# ENCODER0_REG_TOPAZHP_MULTICORE register map
Vendor: Texas Instruments
Peripheral module from a debugger description file (folder J7ES).
Registers are 32-bit, access per field, reset 0x0 unless marked. A register's access mark holds for its fields unless they carry their own. Offsets are as the file gives them; lines under a group give offsets from that group; [hi:lo] are bit positions; {n}, {i} and the like mark numbered series; 'fields as' and 'values as' point back to an identical list; <NAME> marks a mode.

## ENCODER0_REG_TOPAZHP_MULTICORE
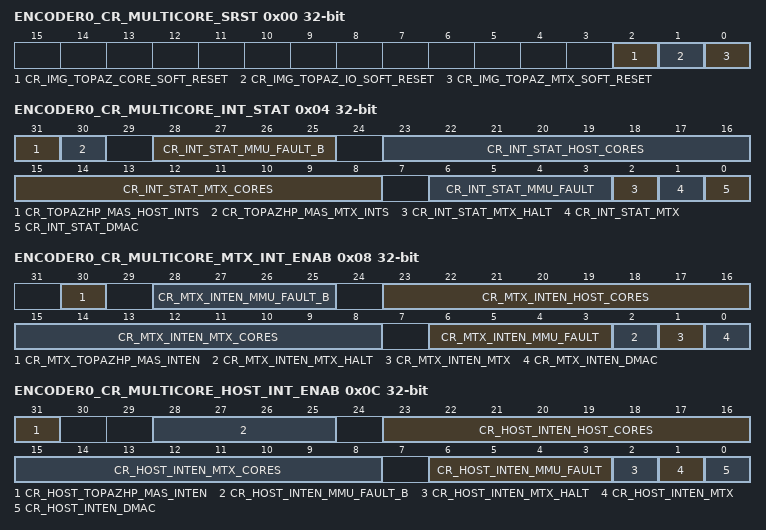
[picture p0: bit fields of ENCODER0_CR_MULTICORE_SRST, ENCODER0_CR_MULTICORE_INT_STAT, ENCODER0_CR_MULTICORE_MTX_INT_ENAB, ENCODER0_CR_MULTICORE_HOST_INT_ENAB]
0x00 ENCODER0_CR_MULTICORE_SRST — It is important that the correct procedure is used when the host software-resets the MTX and the topazHP cores using the MULTICORE_SRST register. This procedure ensures that MTX is inactive before the surrounding logic is reset. Failing to do this may result in the system bus locking up if MTX is active whilst the software reset is used. Disable MTX by writing zero to the MTX_ENABLE register. Software reset MTX only by writing 0x1 then 0x0 to the MULTICORE_SRST register. Software reset MTX, cores, and IO by writing 0x7 then 0x0 to the MULTICORE_SRST register.
  [2] CR_IMG_TOPAZ_CORE_SOFT_RESET rw — Core software reset:
  [1] CR_IMG_TOPAZ_IO_SOFT_RESET rw — IO Software reset:
  [0] CR_IMG_TOPAZ_MTX_SOFT_RESET rw — MTX Software reset:
0x04 ENCODER0_CR_MULTICORE_INT_STAT
  [31] CR_TOPAZHP_MAS_HOST_INTS rw — Status of TopazHP interrupt due to Host enable register
  [30] CR_TOPAZHP_MAS_MTX_INTS rw — Status of TopazHP interrupt due to MTX enable register
  [28:25] CR_INT_STAT_MMU_FAULT_B rw — 4 bit indicating a page fault [Pulse generated at event, held by edge detection logic].
  [23:16] CR_INT_STAT_HOST_CORES rw — Indicates which instances of TopazHP core are currently issuing an IRQ due to the Host enable register.
  [15:8] CR_INT_STAT_MTX_CORES rw — Indicates which instances of TopazHP core are currently issuing an IRQ due to the MTX enable register.
  [6:3] CR_INT_STAT_MMU_FAULT rw — 4 bit indicating a page fault [Pulse generated at event, held by edge detection logic].
  [2] CR_INT_STAT_MTX_HALT rw — MTX_HALT interrupt status
  [1] CR_INT_STAT_MTX rw — MTX interrupt status
  [0] CR_INT_STAT_DMAC rw
0x08 ENCODER0_CR_MULTICORE_MTX_INT_ENAB — Two interrupt signals are generated by the core. The same interrupt sources are used, but different interrupt masks can be applied. This is mainly intended so that one interrupt is used by MTX, and the other interrupt is used by the Host.
  [30] CR_MTX_TOPAZHP_MAS_INTEN rw — Master interrupt enable
  [28:25] CR_MTX_INTEN_MMU_FAULT_B rw — 0 : Disables MMU_FAULT interrupts
  [23:16] CR_MTX_INTEN_HOST_CORES rw — Indicates which instances of TopazHP core CORE_HOST_IRQ are currently enabled as interrupt source.
  [15:8] CR_MTX_INTEN_MTX_CORES rw — Indicates which instances of TopazHP core CORE_MTX_IRQ are currently enabled as interrupt source.
  [6:3] CR_MTX_INTEN_MMU_FAULT rw — 0 : Disables MMU_FAULT interrupts
  [2] CR_MTX_INTEN_MTX_HALT rw
  [1] CR_MTX_INTEN_MTX rw
  [0] CR_MTX_INTEN_DMAC rw
0x0C ENCODER0_CR_MULTICORE_HOST_INT_ENAB
  [31] CR_HOST_TOPAZHP_MAS_INTEN rw — Master interrupt enable
  [28:25] CR_HOST_INTEN_MMU_FAULT_B rw — 0 : Disables MMU_FAULT interrupts
  [23:16] CR_HOST_INTEN_HOST_CORES rw — Indicates which instances of TopazHP core CORE_HOST_IRQ are currently enabled as interrupt source.
  [15:8] CR_HOST_INTEN_MTX_CORES rw — Indicates which instances of TopazHP core CORE_MTX_IRQ are currently enabled as interrupt source.
  [6:3] CR_HOST_INTEN_MMU_FAULT rw — 0 : Disables MMU_FAULT interrupts
  [2] CR_HOST_INTEN_MTX_HALT rw
  [1] CR_HOST_INTEN_MTX rw — 0 : Disables MTX interrupts
  [0] CR_HOST_INTEN_DMAC rw
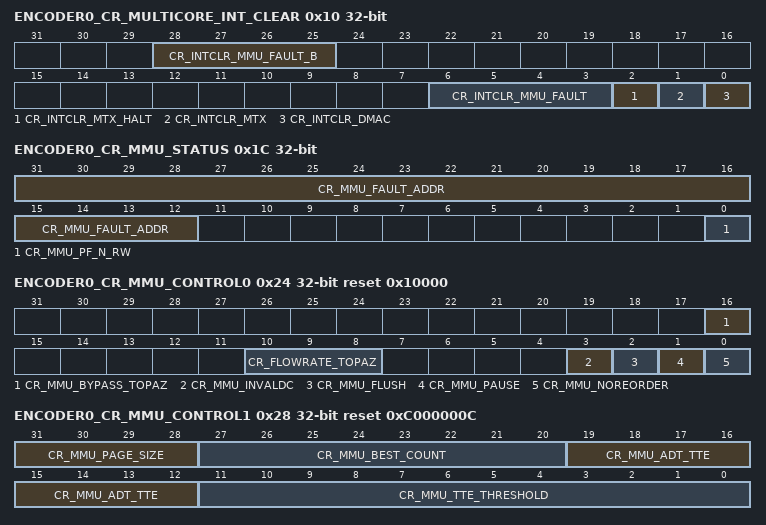
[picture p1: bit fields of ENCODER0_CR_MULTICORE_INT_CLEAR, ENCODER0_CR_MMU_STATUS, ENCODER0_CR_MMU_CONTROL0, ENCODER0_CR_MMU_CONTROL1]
0x10 ENCODER0_CR_MULTICORE_INT_CLEAR — The value read from the MULTICORE_INT_STAT interrupt status register is based on 'input source' ORed with 'rising edge detection' logic. Either the rising edge of a level based interrupt or the rising edge of a pulse inperrupt will be latched by the rising edge detection circuit. Writing '1' to this register clears the relevant 'edge detection' bit in the interrupt status register when the respective bit of write data bit is set. If the edge detect bit is 0, write has no affect. In the case of level based sources, the value read from the interrupt status register will remain high until the source generating the level is cleared. Edge detection logic is not applied to the interrupts generated by each core, because similar status clearing registers exist for each individial source in each core.
  [28:25] CR_INTCLR_MMU_FAULT_B rw — 1 : Clear MMU fault interrupt [clears fault caused by either TopazHP cores or by the DMAC]
  [6:3] CR_INTCLR_MMU_FAULT rw — 1 : Clear MMU fault interrupt [clears fault caused by either TopazHP cores or by the DMAC]
  [2] CR_INTCLR_MTX_HALT rw
  [1] CR_INTCLR_MTX rw
  [0] CR_INTCLR_DMAC rw
0x14 ENCODER0_CR_MULTICORE_MAN_CLK_GATE
  [1] CR_TOPAZ_MTX_MAN_CLK_GATE rw — MTX manual clock gate:
0x18 ENCODER0_CR_TOPAZ_MTX_C_RATIO — Reserved for internal use
  [1:0] CR_MTX_C_RATIO rw — sys_clk : mtx_clk clock ratio
0x1C ENCODER0_CR_MMU_STATUS ro
  [31:12] CR_MMU_FAULT_ADDR — Page-aligned address causing page fault
  [0] CR_MMU_PF_N_RW — Indicates whether the current fault is a page or R/W protection fault
0x20 ENCODER0_CR_MMU_MEM_REQ ro
  [7:0] CR_MEM_REQ_STAT_READS — This is the number of outstanding read requests.
0x24 ENCODER0_CR_MMU_CONTROL0 reset 0x10000
  [16] CR_MMU_BYPASS_TOPAZ rw — Setting this bit to a '1' bypasses the MMU for the TopazHP cores and the DMAC
  [10:8] CR_FLOWRATE_TOPAZ rw — Flowrate control for TopazHP cores
  [3] CR_MMU_INVALDC rw — Writing '1' causes flushing of directory cache [and all other caches and tlbs] [The flush is triggered by the act of writing '1' to this bit, but the flush will complete and MMU will continue to function if the bit is left high.
  [2] CR_MMU_FLUSH rw — Writing '1' causes flushing of address translation cache and all tlbs [The MMU will remain in Flush state until the bit is cleared by writing '0'.
  [1] CR_MMU_PAUSE rw — Writing '1' causes MMU operation to pause [The MMU will remain paused until the bit is cleared by writing '0']
  [0] CR_MMU_NOREORDER rw — Writing '1' disables transaction re-ordering by signalling to the external SoC infrastructure to closely order the requests [debug only]
0x28 ENCODER0_CR_MMU_CONTROL1 rw reset 0xC000000C
  [31:28] CR_MMU_PAGE_SIZE — Page size control for memory arbiter - the value corresponds to the lsb position of the page size
  [27:20] CR_MMU_BEST_COUNT — Best count for memory arbiter
  [19:12] CR_MMU_ADT_TTE — TTE value for ADT
  [11:0] CR_MMU_TTE_THRESHOLD — TTE threshold for memory arbiter
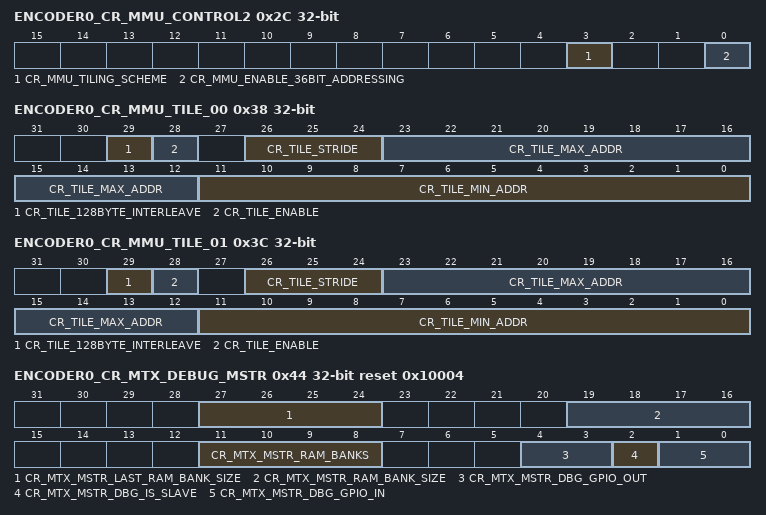
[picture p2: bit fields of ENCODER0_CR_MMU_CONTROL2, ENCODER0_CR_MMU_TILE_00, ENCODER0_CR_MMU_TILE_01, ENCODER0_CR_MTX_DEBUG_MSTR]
0x2C ENCODER0_CR_MMU_CONTROL2
  [3] CR_MMU_TILING_SCHEME rw — This bit controls the tiling scheme described in MMU Address Translation section.
  [0] CR_MMU_ENABLE_36BIT_ADDRESSING rw — Setting this bit to a value of 1 enables the extended MMU addressing [i.e.
0x30 ENCODER0_CR_MMU_DIR_LIST_BASE_00
  [31:4] CR_MMU_DIR_LIST_BASE_ADDR rw — Base address in physical memory for MMU Directory 1 Entries.
0x38 ENCODER0_CR_MMU_TILE_00
  [29] CR_TILE_128BYTE_INTERLEAVE rw — If DDR is arranged so that 128 bytes go to one bank, and the next 128 bytes go to a different bank row accesses into a tile could be more efficient if they swap order every 128 bytes
  [28] CR_TILE_ENABLE rw — 0 : Memory Tiling Disabled
  [26:24] CR_TILE_STRIDE rw — Defines the X Tile Stride for the memory address range
  [23:12] CR_TILE_MAX_ADDR rw — Defines the address for tiling range, in trems of the address MSB's i.e.
  [11:0] CR_TILE_MIN_ADDR rw — Defines the minimum address for range tiling range, in terms of the address MSB's i.e.
0x3C ENCODER0_CR_MMU_TILE_01
  fields as ENCODER0_CR_MMU_TILE_00
0x44 ENCODER0_CR_MTX_DEBUG_MSTR reset 0x10004
  [27:24] CR_MTX_MSTR_LAST_RAM_BANK_SIZE rw — Defines size of last RAM bank, where size is 2^[MTX_LAST_RAM_BANK_SIZE+2] bytes
  [19:16] CR_MTX_MSTR_RAM_BANK_SIZE rw — Defines size of all but last bank, where size is 2^[MTX_RAM_BANK_SIZE+2] bytes
  [11:8] CR_MTX_MSTR_RAM_BANKS rw — Number of MTX RAM banks
  [4:3] CR_MTX_MSTR_DBG_GPIO_OUT rw — Data provided by dbg_gpio_out by MTX.
  [2] CR_MTX_MSTR_DBG_IS_SLAVE rw — Determines whether the jtag port of MTX is to be master or slave
  [1:0] CR_MTX_MSTR_DBG_GPIO_IN rw — Data for dbg_gpio_in for MTX
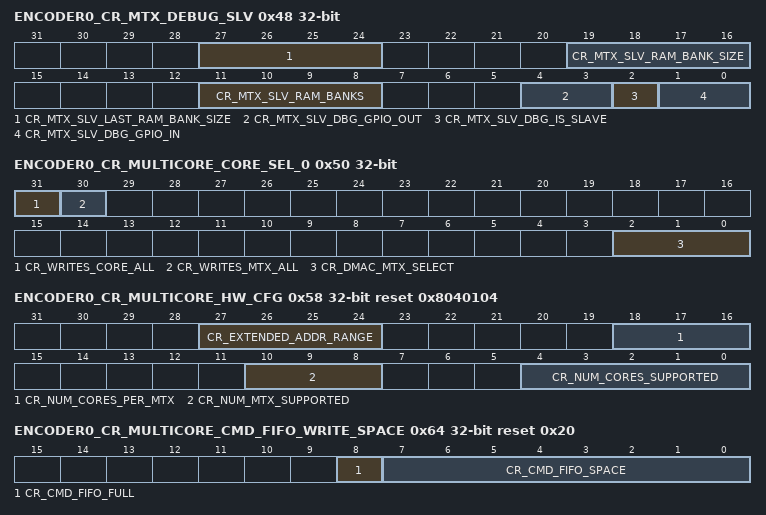
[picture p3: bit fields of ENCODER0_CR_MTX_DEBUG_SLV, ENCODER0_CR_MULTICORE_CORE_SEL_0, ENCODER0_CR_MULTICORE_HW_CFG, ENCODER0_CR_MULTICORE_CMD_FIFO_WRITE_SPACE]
0x48 ENCODER0_CR_MTX_DEBUG_SLV
  [27:24] CR_MTX_SLV_LAST_RAM_BANK_SIZE rw — Defines size of last RAM bank, where size is 2^[MTX_LAST_RAM_BANK_SIZE+2] bytes
  [19:16] CR_MTX_SLV_RAM_BANK_SIZE rw — Defines size of all but last bank, where size is 2^[MTX_RAM_BANK_SIZE+2] bytes
  [11:8] CR_MTX_SLV_RAM_BANKS rw — Number of MTX RAM banks
  [4:3] CR_MTX_SLV_DBG_GPIO_OUT rw — Data provided by dbg_gpio_out by MTX.
  [2] CR_MTX_SLV_DBG_IS_SLAVE rw — Determines whether the jtag port of MTX is to be master or slave
  [1:0] CR_MTX_SLV_DBG_GPIO_IN rw — Data for dbg_gpio_in for MTX
0x50 ENCODER0_CR_MULTICORE_CORE_SEL_0
  [31] CR_WRITES_CORE_ALL rw — 0 : Write accesses will be sent to one instance of TopazHP core depending on the address
  [30] CR_WRITES_MTX_ALL rw — 0 : Write accesses will be sent to one MTX depending on the address
  [2:0] CR_DMAC_MTX_SELECT rw — The topaz_core number to which a DMA transfer is targeted.
0x54 ENCODER0_CR_MULTICORE_CORE_SEL_1
  [4:0] CR_RTM_PORT_CORE_SELECT rw — The number of the instance of TopazHP core to which the external RTM ports will be connected
0x58 ENCODER0_CR_MULTICORE_HW_CFG ro reset 0x8040104
  [27:24] CR_EXTENDED_ADDR_RANGE — The number of physical address bits - 32, where a value of 0 indicates
  [18:16] CR_NUM_CORES_PER_MTX — The number of TopazHP cores that are controlled by each MTX
  [10:8] CR_NUM_MTX_SUPPORTED — The number of instances of MTX that are present
  [4:0] CR_NUM_CORES_SUPPORTED — The number of instances of TopazHP core that are present
0x60 ENCODER0_CR_MULTICORE_CMD_FIFO_WRITE rw
  [31:0] CR_CMD_FIFO_WDATA — Data written to this register is stored into the command FIFO.
0x64 ENCODER0_CR_MULTICORE_CMD_FIFO_WRITE_SPACE ro reset 0x20
  [8] CR_CMD_FIFO_FULL — 0 : The command FIFO has space in it for at least 1 word
  [7:0] CR_CMD_FIFO_SPACE — The number of words of space available in the command FIFO.
0x70 ENCODER0_CR_TOPAZ_CMD_FIFO_READ rw
  [31:0] CR_CMD_FIFO_RDATA — Data from the command FIFO can be read by reading this register.
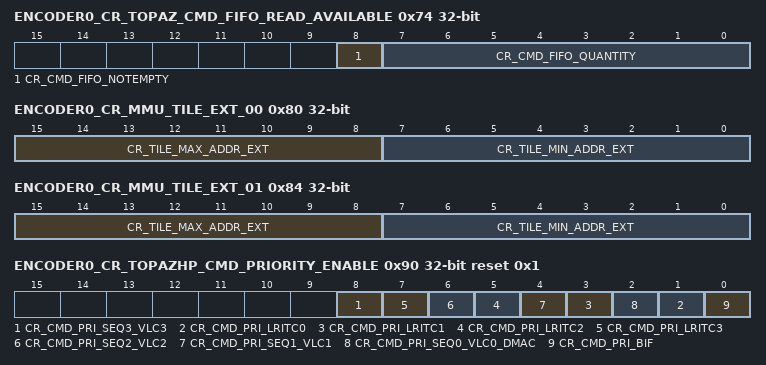
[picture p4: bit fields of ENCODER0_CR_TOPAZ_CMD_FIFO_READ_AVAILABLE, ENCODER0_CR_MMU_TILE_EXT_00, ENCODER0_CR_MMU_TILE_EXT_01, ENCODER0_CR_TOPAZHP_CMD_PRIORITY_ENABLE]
0x74 ENCODER0_CR_TOPAZ_CMD_FIFO_READ_AVAILABLE ro
  [8] CR_CMD_FIFO_NOTEMPTY — 0 : The command FIFO is empty.
  [7:0] CR_CMD_FIFO_QUANTITY — The number of words of data that are available to be read from the command FIFO
0x78 ENCODER0_CR_TOPAZ_CMD_FIFO_FLUSH
  [0] CR_CMD_FIFO_FLUSH rw — The action of writing 1 to this register causes all the data currently in the command FIFO to be discarded.
0x80 ENCODER0_CR_MMU_TILE_EXT_00
  [15:8] CR_TILE_MAX_ADDR_EXT rw — Defines the extended part of max address for tiling range, in terms of the address LSB's i.e.
  [7:0] CR_TILE_MIN_ADDR_EXT rw — Defines the extended part of min address for tiling range, in terms of the address LSB's i.e.
0x84 ENCODER0_CR_MMU_TILE_EXT_01
  fields as ENCODER0_CR_MMU_TILE_EXT_00
0x90 ENCODER0_CR_TOPAZHP_CMD_PRIORITY_ENABLE reset 0x1 — This register enables the mem_cmd_priority output for each TopazHP BIF requestor individually. The mem_cmd_priority output is set per memory transaction to indicate to the bus fabric that the transaction is more critical to performance than other requests. Each requestor may have the priority enabled independently. The BIF defaults to high priority on reset for MMU page tables. Note that high priority transactions (as enabled by this register) will not be stalled when the mem_limited_throughput input is set. Transactions issued by the BIF for MMU page table fetches will never be stalled regardless of whether the CMD_PRI_BIF register bit is set.
  [8] CR_CMD_PRI_SEQ3_VLC3 rw — The mem_cmd_priority output may be set for SEQ3 / VLC3 memory transactions when enabled.
  [2n+1] CR_CMD_PRI_LRITC{n} rw (n=0..3) — The mem_cmd_priority output may be set for LRITC{n} memory transactions when enabled.
  [6] CR_CMD_PRI_SEQ2_VLC2 rw — The mem_cmd_priority output may be set for SEQ2 / VLC2 memory transactions when enabled.
  [4] CR_CMD_PRI_SEQ1_VLC1 rw — The mem_cmd_priority output may be set for SEQ1 / VLC1 memory transactions when enabled.
  [2] CR_CMD_PRI_SEQ0_VLC0_DMAC rw — The mem_cmd_priority output may be set for SEQ0 / VLC0 / DMAC memory transactions when enabled.
  [0] CR_CMD_PRI_BIF rw — The mem_cmd_priority output may be set for BIF [MMU] memory transactions when enabled.
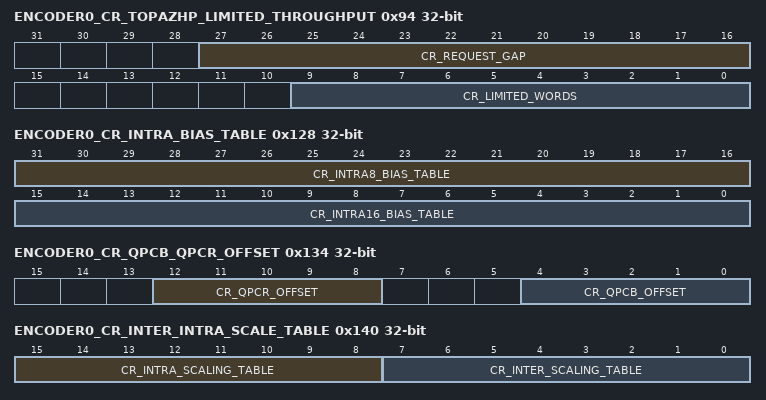
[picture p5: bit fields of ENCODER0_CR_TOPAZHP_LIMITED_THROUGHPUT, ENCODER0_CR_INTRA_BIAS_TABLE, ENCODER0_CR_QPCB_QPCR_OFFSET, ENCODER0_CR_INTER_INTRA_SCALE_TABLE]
0x94 ENCODER0_CR_TOPAZHP_LIMITED_THROUGHPUT — This register controls the memory bus stalling behaviour which occurs when the mem_limited_thrughput input is set. The mem_limited_throughput input is set by the bus fabric to indicate to TopazHP that the bus infrastructure is becoming saturated and that higher priority requests should not be blocked by lower priority requests. When the mem_limited_throughput input is set, no additional normal priority requests (with the exception of BIF (MMU) requests) are made for the duration of the request gap (counting the REQUEST_GAP number of clock cycles). Once the request gap is complete, the number of words of normal priority requests is counted up to the limited number of words (LIMITED_WORDS). Any burst transactions in progress are allowed to complete before stalling of normal priority requests recommences for the duration of the request gap. When the mem_limited_throughput input is cleared the counters are disabled (set to zero) and all requests proceed without limit. High priority requests (as defined by the CMD_PRIORITY_ENABLE register) are not stalled and pass unheeded. Requests issued by the BIF for MMU page table fetches always pass unheeded regardless of the value in the CMD_PRIORITY_ENABLE register. When either REQUEST_GAP or LIMITED_WORDS is set to zero the counters are disabled (set to zero) and all memory requests pass unheeded.
  [27:16] CR_REQUEST_GAP rw — Number of clock cycles in the range {0,4095} for which normal priority memory requests are stalled when the mem_limited_throughput input is set.
  [9:0] CR_LIMITED_WORDS rw — Number of normal priority words in the range {0,1023} that can be issued by all requestors combined before applying a request gap when the mem_limited_throughput input is set.
{0xFC+4i} ENCODER0_CR_FIRMWARE_REG_{i} rw (i=1..3)
  [31:0] CR_FIRMWARE_REG_{i} — General purpose register for software use
0x110 ENCODER0_CR_CYCLE_COUNTER rw — This counter can be used to keep track of the rate at which the core is encoding macroblocks. To measure frame rate, clear at the start of a frame and read back the value at the end of the frame.
  [31:0] CR_CYCLE_COUNTER — 32-bit cycle counter, when enabled increments by 1 each clock cycle.
0x114 ENCODER0_CR_CYCLE_COUNTER_CTRL
  [0] CR_CYCLE_COUNTER_ENABLE rw
0x118 ENCODER0_CR_MULTICORE_IDLE_PWR_MAN
  [0] CR_TOPAZ_IDLE_DISABLE rw — This field can be used to disable the topaz_idle power management output.
0x124 ENCODER0_CR_DIRECT_BIAS_TABLE — The input to the Direct_Bias shift register based table. Direct_Bias is used to bias selection towards selecting Direct mode output, which is Skip MV(P slice)/Direct mode(Bslice).
  [14:0] CR_DIRECT_BIAS_TABLE rw — Link to the Direct bias table, which is shift register based [52 entries]
0x128 ENCODER0_CR_INTRA_BIAS_TABLE rw
  [31:16] CR_INTRA8_BIAS_TABLE — Firmware stores the signed INTRA_8x8_BIAS table entries here in decrementing order [27 entries]
  [15:0] CR_INTRA16_BIAS_TABLE — Firmware stores the signed INTRA_16x16_BIAS table entries here in decrementing order [27 entries]
0x12C ENCODER0_CR_INTER_BIAS_TABLE — Firmware store the SPE_INTER_BIAS table entries here one by one in decrementing order.
  [15:0] CR_INTER_BIAS_TABLE rw — Firmware store the signed INTER_BIAS table entries here in decrementing order [27 entries]
0x130 ENCODER0_CR_INTRA_SCALE_TABLE
  [2:0] CR_INTRA8_SCALE_TABLE rw — Firmware stores the signed INTRA_8x8_SCALE table entries here in decrementing order [27 entries]
0x134 ENCODER0_CR_QPCB_QPCR_OFFSET
  [12:8] CR_QPCR_OFFSET rw — Signed offset added to QPy [and then clipped to range 0 to 51] which is used to look-up QPCr from the QPC lookup table.
  [4:0] CR_QPCB_OFFSET rw — Signed offset added to QPy [and then clipped to range 0 to 51] which is used to look-up QPCb from the QPC lookup table.
0x140 ENCODER0_CR_INTER_INTRA_SCALE_TABLE
  [15:8] CR_INTRA_SCALING_TABLE rw — Firmware stores the INTRA_SCALING table here in decrementing order [8 entries]
  [7:0] CR_INTER_SCALING_TABLE rw — Firmware stores the INTER_SCALING table here in decrementing order [8 entries]
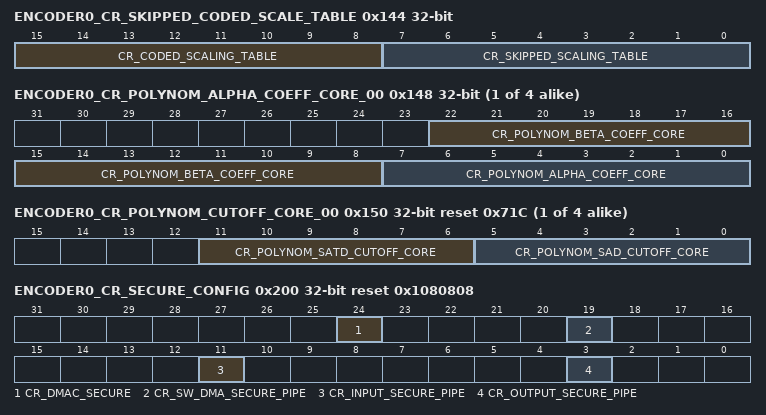
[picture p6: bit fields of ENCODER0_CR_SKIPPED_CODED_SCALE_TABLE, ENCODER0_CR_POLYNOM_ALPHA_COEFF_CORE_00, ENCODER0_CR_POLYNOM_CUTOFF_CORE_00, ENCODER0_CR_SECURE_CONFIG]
0x144 ENCODER0_CR_SKIPPED_CODED_SCALE_TABLE
  [15:8] CR_CODED_SCALING_TABLE rw — Firmware stores the CODED_SCALING table here in decrementing order [8 entries]
  [7:0] CR_SKIPPED_SCALING_TABLE rw — Firmware stores the SKIPPED_SCALING table here in decrementing order [8 entries]
{0x148+0xC*i} ENCODER0_CR_POLYNOM_ALPHA_COEFF_CORE_{i:02} (i=0..3) — alpha and betta coeffs for lambda table polynomial
  [22:8] CR_POLYNOM_BETA_COEFF_CORE rw — beta coeff for the lambda polynomial [x term], shift register, shift in the following order.
  [7:0] CR_POLYNOM_ALPHA_COEFF_CORE rw — alpha coeff for the lambda polynomial [x squared term], shift register, shift in the following order.
{0x14C+0xC*i} ENCODER0_CR_POLYNOM_GAMMA_COEFF_CORE_{i:02} (i=0..3)
  [17:0] CR_POLYNOM_GAMMA_COEFF_CORE rw — Gamma coeff for the lambda polynomial [constant term], shift register, shift in the following order
{0x150+0xC*i} ENCODER0_CR_POLYNOM_CUTOFF_CORE_{i:02} reset 0x71C (i=0..3)
  [11:6] CR_POLYNOM_SATD_CUTOFF_CORE rw — Cutoff for the change between the lower and higher qp set of coeffs for the polynomial, greater or equal to this value of qp the polynomial uses the second set of coeffs.
  [5:0] CR_POLYNOM_SAD_CUTOFF_CORE rw — Cutoff for the change between the lower and higher qp set of coeffs for the polynomial, greater or equal to this value of qp the polynomial uses the second set of coeffs.
0x200 ENCODER0_CR_SECURE_CONFIG reset 0x1080808 — This register controls the 'secure' status of AXI memory bus transactions issued by the encoder. On devices that are configured to use the IMGBus2 memory bus interface this register should not be used.
  [24] CR_DMAC_SECURE rw — 0: Memory bus transactions issued by the DMAC are marked as 'non-secure'
  [19] CR_SW_DMA_SECURE_PIPE rw — 0: Memory bus transactions issued by the S/W DMA are marked as 'non-secure'
  [11] CR_INPUT_SECURE_PIPE rw — 0: Memory bus transactions issued by the encoder for reading in current pixel data are marked as 'non-secure'
  [3] CR_OUTPUT_SECURE_PIPE rw — 0: Memory bus transactions issued by the encoder for the following data categories are marked as 'non-secure'
{0x2F0+4i} ENCODER0_CR_FIRMWARE_REG_{i} rw (i=4..7)
  fields as ENCODER0_CR_FIRMWARE_REG_1
0x3B0 ENCODER0_CR_MULTICORE_RSVD0
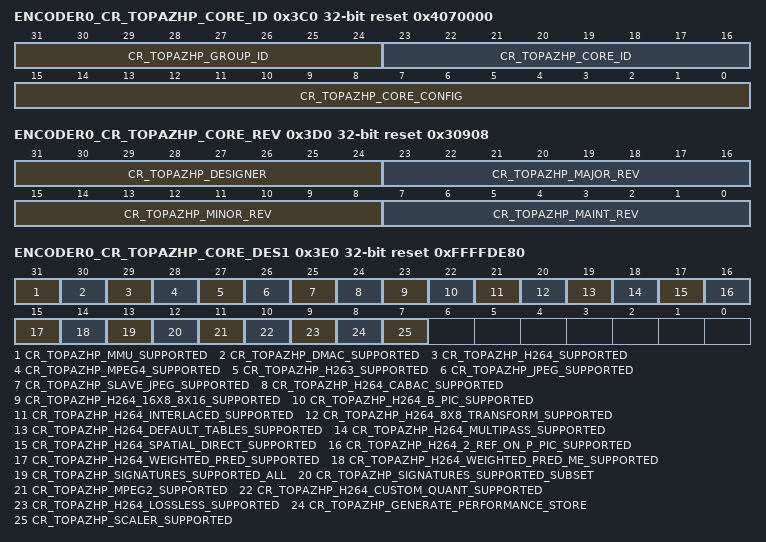
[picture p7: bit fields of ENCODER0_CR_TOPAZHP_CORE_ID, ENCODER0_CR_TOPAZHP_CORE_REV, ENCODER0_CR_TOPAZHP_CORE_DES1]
0x3C0 ENCODER0_CR_TOPAZHP_CORE_ID ro reset 0x4070000
  [31:24] CR_TOPAZHP_GROUP_ID — This identifies the as part of an IMG IP family group.
  [23:16] CR_TOPAZHP_CORE_ID — This identifies the member of the Ip group
  [15:0] CR_TOPAZHP_CORE_CONFIG — IMG Core Configuration.
0x3D0 ENCODER0_CR_TOPAZHP_CORE_REV ro reset 0x30908
  [31:24] CR_TOPAZHP_DESIGNER — Designer Code
  [23:16] CR_TOPAZHP_MAJOR_REV — IMG Family Major Revision
  [15:8] CR_TOPAZHP_MINOR_REV — IMG Core Minor Revision
  [7:0] CR_TOPAZHP_MAINT_REV — IMG Maintenance Revision
0x3E0 ENCODER0_CR_TOPAZHP_CORE_DES1 ro reset 0xFFFFDE80 — This register contains fields indicating which settings were enabled in the custom pack for this instance of the core.
  [31] CR_TOPAZHP_MMU_SUPPORTED — When set, this indicates that MMU support is enabled in this module.
  [30] CR_TOPAZHP_DMAC_SUPPORTED — When set, this indicates that DMAC support is enabled in this module.
  [29] CR_TOPAZHP_H264_SUPPORTED — When set, this indicates that H264 support is enabled in this module.
  [28] CR_TOPAZHP_MPEG4_SUPPORTED — When set, this indicates that MPEG4 support is enabled in this module.
  [27] CR_TOPAZHP_H263_SUPPORTED — When set, this indicates that H.236 support is enabled in this module.
  [26] CR_TOPAZHP_JPEG_SUPPORTED — When set, this indicates that JPEG support is enabled on pipe 0 in this module.
  [25] CR_TOPAZHP_SLAVE_JPEG_SUPPORTED — When set, this indicates that JPEG support is enabled on other pipes in this module.
  [24] CR_TOPAZHP_H264_CABAC_SUPPORTED — When set, this indicates that CABAC support is enabled in this module.
  [23] CR_TOPAZHP_H264_16X8_8X16_SUPPORTED — When set, this indicates that 16x8 and 8x16 macroblock partition support is enabled in this module.
  [22] CR_TOPAZHP_H264_B_PIC_SUPPORTED — When set, this indicates that B picture support is enabled in this module.
  [21] CR_TOPAZHP_H264_INTERLACED_SUPPORTED — When set, this indicates that H264 interlace support is enabled in this module.
  [20] CR_TOPAZHP_H264_8X8_TRANSFORM_SUPPORTED — When set, this indicates that H264 8x8 transform is enabled in this module.
  [19] CR_TOPAZHP_H264_DEFAULT_TABLES_SUPPORTED — When set, this indicates that H264 default scaling list quantisation support is enabled in this module.
  [18] CR_TOPAZHP_H264_MULTIPASS_SUPPORTED — When set, this indicates that multipass support is enabled in this module.
  [17] CR_TOPAZHP_H264_SPATIAL_DIRECT_SUPPORTED — When set, this indicates that spatial direct mode support is enabled in this module.
  [16] CR_TOPAZHP_H264_2_REF_ON_P_PIC_SUPPORTED — When set, this indicates that the use of 2 reference pictures on a P picture is enabled in this module.
  [15] CR_TOPAZHP_H264_WEIGHTED_PRED_SUPPORTED — When set, this indicates that weighted prediction support is enabled in this module.
  [14] CR_TOPAZHP_H264_WEIGHTED_PRED_ME_SUPPORTED — When set, this indicates that weighted prediction support [for motion estimation] is enabled in this module.
  [13] CR_TOPAZHP_SIGNATURES_SUPPORTED_ALL — When set, this indicates that all signature registers are enabled in this module.
  [12] CR_TOPAZHP_SIGNATURES_SUPPORTED_SUBSET — When set, this indicates that a subset of the signature registers are enabled in this module.
  [11] CR_TOPAZHP_MPEG2_SUPPORTED — When set, this indicates that MPEG2 support is enabled in this module.
  [10] CR_TOPAZHP_H264_CUSTOM_QUANT_SUPPORTED — When set, this indicates that custom quantisation table support is enabled in this module.
  [9] CR_TOPAZHP_H264_LOSSLESS_SUPPORTED — When set, this indicates that lossless compression support is enabled in this module.
  [8] CR_TOPAZHP_GENERATE_PERFORMANCE_STORE — When set, this indicates that MMU support is enabled in this module.
  [7] CR_TOPAZHP_SCALER_SUPPORTED — When set, this indicates that support for down-scaling the input picture for video encode is enabled in this module.
0x3F0 ENCODER0_CR_TOPAZHP_CORE_DES2 ro — The SOC designer can use this register for their own revision control.
  [31:0] CR_TOPAZHP_DESIGNER2 — Designer Revision Field2
